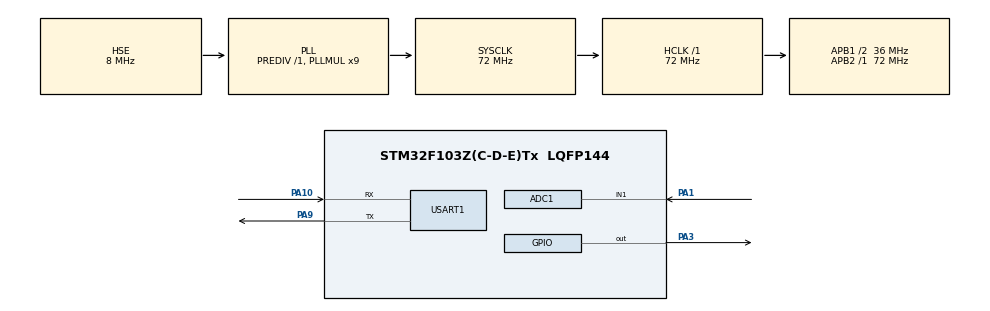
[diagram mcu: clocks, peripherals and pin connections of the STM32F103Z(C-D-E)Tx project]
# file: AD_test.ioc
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ADC1.Channel-0\#ChannelRegularConversion=ADC_CHANNEL_1
ADC1.ContinuousConvMode=DISABLE
ADC1.DataAlign=ADC_DATAALIGN_RIGHT
ADC1.DiscontinuousConvMode=DISABLE
ADC1.EnableAnalogWatchDog=false
ADC1.EnableRegularConversion=ENABLE
ADC1.ExternalTrigConv=ADC_SOFTWARE_START
ADC1.InjNumberOfConversion=0
ADC1.NbrOfConversion=1
ADC1.NbrOfConversionFlag=1
ADC1.Rank-0\#ChannelRegularConversion=1
ADC1.SamplingTime-0\#ChannelRegularConversion=ADC_SAMPLETIME_55CYCLES_5
ADC1.ScanConvMode=ADC_SCAN_DISABLE
ADC1.master=1
Mcu.Family=STM32F1
Mcu.Name=STM32F103Z(C-D-E)Tx
Mcu.Package=LQFP144
NVIC.ADC1_2_IRQn=true\:0\:0\:true\:false\:true\:true
NVIC.PriorityGroup=NVIC_PRIORITYGROUP_2
NVIC.TIM3_IRQn=true\:1\:0\:true\:false\:true\:true
OSC_IN.Mode=HSE-External-Oscillator
OSC_IN.Signal=RCC_OSC_IN
OSC_OUT.Mode=HSE-External-Oscillator
OSC_OUT.Signal=RCC_OSC_OUT
PA1.Signal=ADCx_IN1
PA10.Mode=Asynchronous
PA10.Signal=USART1_RX
PA13.Mode=Serial_Wire
PA13.Signal=SYS_JTMS-SWDIO
PA14.Mode=Serial_Wire
PA14.Signal=SYS_JTCK-SWCLK
PA3.GPIO_PuPd=GPIO_PULLDOWN
PA3.Signal=GPIO_Output
PA9.Mode=Asynchronous
PA9.Signal=USART1_TX
ProjectManager.HeapSize=0x200
ProjectManager.StackSize=0x400
ProjectManager.TargetToolchain=MDK-ARM V5
RCC.ADCPresc=RCC_ADCPCLK2_DIV6
RCC.AHBFreq_Value=72000000
RCC.APB1CLKDivider=RCC_HCLK_DIV2
RCC.APB1Freq_Value=36000000
RCC.APB1TimFreq_Value=72000000
RCC.APB2Freq_Value=72000000
RCC.APB2TimFreq_Value=72000000
RCC.HCLKFreq_Value=72000000
RCC.PLLMUL=RCC_PLL_MUL9
RCC.PLLSourceVirtual=RCC_PLLSOURCE_HSE
RCC.SYSCLKFreq_VALUE=72000000
RCC.SYSCLKSource=RCC_SYSCLKSOURCE_PLLCLK
RCC.USBFreq_Value=72000000
SH.ADCx_IN1.0=ADC1_IN1,IN1
TIM3.Period=1000
TIM3.Prescaler=72
USART1.VirtualMode=VM_ASYNC
VP_TIM3_VS_ClockSourceINT.Mode=Internal
board=custom

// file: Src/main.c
/**
  ******************************************************************************
  * @file           : main.c
  * @brief          : Main program body
  ******************************************************************************
  ** This notice applies to any and all portions of this file
  * that are not between comment pairs USER CODE BEGIN and
  * USER CODE END. Other portions of this file, whether
  * inserted by the user or by software development tools
  * are owned by their respective copyright owners.
  *
  * COPYRIGHT(c) 2018 STMicroelectronics
  *
  * Redistribution and use in source and binary forms, with or without modification,
  * are permitted provided that the following conditions are met:
  *   1. Redistributions of source code must retain the above copyright notice,
  *      this list of conditions and the following disclaimer.
  *   2. Redistributions in binary form must reproduce the above copyright notice,
  *      this list of conditions and the following disclaimer in the documentation
  *      and/or other materials provided with the distribution.
  *   3. Neither the name of STMicroelectronics nor the names of its contributors
  *      may be used to endorse or promote products derived from this software
  *      without specific prior written permission.
  *
  * THIS SOFTWARE IS PROVIDED BY THE COPYRIGHT HOLDERS AND CONTRIBUTORS "AS IS"
  * AND ANY EXPRESS OR IMPLIED WARRANTIES, INCLUDING, BUT NOT LIMITED TO, THE
  * IMPLIED WARRANTIES OF MERCHANTABILITY AND FITNESS FOR A PARTICULAR PURPOSE ARE
  * DISCLAIMED. IN NO EVENT SHALL THE COPYRIGHT HOLDER OR CONTRIBUTORS BE LIABLE
  * FOR ANY DIRECT, INDIRECT, INCIDENTAL, SPECIAL, EXEMPLARY, OR CONSEQUENTIAL
  * DAMAGES (INCLUDING, BUT NOT LIMITED TO, PROCUREMENT OF SUBSTITUTE GOODS OR
  * SERVICES; LOSS OF USE, DATA, OR PROFITS; OR BUSINESS INTERRUPTION) HOWEVER
  * CAUSED AND ON ANY THEORY OF LIABILITY, WHETHER IN CONTRACT, STRICT LIABILITY,
  * OR TORT (INCLUDING NEGLIGENCE OR OTHERWISE) ARISING IN ANY WAY OUT OF THE USE
  * OF THIS SOFTWARE, EVEN IF ADVISED OF THE POSSIBILITY OF SUCH DAMAGE.
  *
  ******************************************************************************
  */
#include "main.h"
#include "stm32f1xx_hal.h"

ADC_HandleTypeDef hadc1;

TIM_HandleTypeDef htim3;

UART_HandleTypeDef huart1;

/* USER CODE BEGIN PV */
/* Private variables ---------------------------------------------------------*/

/* USER CODE END PV */

void SystemClock_Config(void);
static void MX_GPIO_Init(void);
static void MX_ADC1_Init(void);
static void MX_USART1_UART_Init(void);
static void MX_TIM3_Init(void);

/* USER CODE BEGIN PFP */
/* Private function prototypes -----------------------------------------------*/

/* USER CODE END PFP */

/* USER CODE BEGIN 0 */
uint16_t AD_Value = 0;
float Value_1[10000]={0};
float Value_2[5000]={0};
float AD=0;
int i=-1;
float a=0; //加速度大小
//int p=0;
/* USER CODE END 0 */

int main(void)
{

  /* MCU Configuration----------------------------------------------------------*/

  /* Reset of all peripherals, Initializes the Flash interface and the Systick. */
  HAL_Init();

  /* Configure the system clock */
  SystemClock_Config();

  /* Initialize all configured peripherals */
  MX_GPIO_Init();
  MX_ADC1_Init();
  MX_USART1_UART_Init();
  MX_TIM3_Init();
  /* USER CODE BEGIN 2 */
	HAL_ADCEx_Calibration_Start(&hadc1);	//AD校准
  //HAL_Delay(3000);
	HAL_TIM_Base_Start_IT(&htim3); //启动定时器中断
	//HAL_TIM_Base_Stop_IT(&htim3);//关中断
  /* USER CODE END 2 */

  /* Infinite loop */
  while (1)
  {

  /* USER CODE BEGIN 3 */
		//HAL_ADC_Start_IT(&hadc1);
/*			HAL_ADC_Start(&hadc1);
			HAL_ADC_PollForConversion(&hadc1, 1000);	//等待转换完成，第二个参数表示超时时间，单位ms
			if(HAL_IS_BIT_SET(HAL_ADC_GetState(&hadc1), HAL_ADC_STATE_REG_EOC))
			{
				AD_Value=HAL_ADC_GetValue(&hadc1);
				AD=(float)(AD_Value*3.3/4096);
				printf("AD = %.3f \r\n",AD);
				a = (AD*1000)/(50.17*10);
				printf("%.4f \r\n",a);//HAL_Delay(1000);
			}
  htim3.Init.Prescaler = 72-1;
  htim3.Init.CounterMode = TIM_COUNTERMODE_UP;
  htim3.Init.Period = 250-1; ////计数值2000，定时2ms 1M/2ms=500次/s ， 计数值1000，定时1ms 1M/1ms=1000次/s ， 计数值500，定时500us 1M/1ms=2000次/s ，计数值250，定时250us 1M/1ms=4000次/s
		==
void HAL_TIM_PeriodElapsedCallback(TIM_HandleTypeDef *htim)
{
	HAL_ADC_Start_IT(&hadc1);
	//HAL_GPIO_TogglePin(GPIOA,GPIO_PIN_3);
}
void HAL_ADC_ConvCpltCallback(ADC_HandleTypeDef* hadc)
{
	HAL_ADC_Stop_IT(&hadc1);
	i++;
	AD_Value=HAL_ADC_GetValue(&hadc1);
	//printf("%d\r\n",i);
	if(i<10000) //0-9999
		Value_1[i]=(float)(AD_Value*3.3/4096)*1000;
	else //10000-19999
		Value_2[i-10000]=(float)(AD_Value*3.3/4096)*1000;

	if(i==14999)
	{
		HAL_TIM_Base_Stop_IT(&htim3);
		for(int j=0;j<10000;j++)
			printf("%.4f , %d\r\n",Value_1[j],j);
		for(int j=10000;j<15000;j++)
			printf("%.4f , %d\r\n",Value_2[j-10000],j-10000);
		i=-1;
		HAL_TIM_Base_Start_IT(&htim3);
	}
}
		*/
	}
  /* USER CODE END 3 */

}
void HAL_TIM_PeriodElapsedCallback(TIM_HandleTypeDef *htim)
{
	HAL_ADC_Start_IT(&hadc1);
	//HAL_GPIO_TogglePin(GPIOA,GPIO_PIN_3);
}
void HAL_ADC_ConvCpltCallback(ADC_HandleTypeDef* hadc)
{
	HAL_ADC_Stop_IT(&hadc1);	//关闭ADC
	i++;
	AD_Value=HAL_ADC_GetValue(&hadc1);
	//printf("%d\r\n",i);
	if(i<10000) //0-9999
		Value_1[i]=(float)(AD_Value*3.3/4096)*1000;
	else //10000-19999
		Value_2[i-10000]=(float)(AD_Value*3.3/4096)*1000;

	if(i==14999)
	{
		HAL_TIM_Base_Stop_IT(&htim3);
		for(int j=0;j<10000;j++)
			printf("%.4f \r\n",Value_1[j]);
		for(int j=10000;j<15000;j++)
			printf("%.4f\r\n",Value_2[j-10000]);
		i=-1;
		HAL_TIM_Base_Start_IT(&htim3);
	}
}
void SystemClock_Config(void)
{

  RCC_OscInitTypeDef RCC_OscInitStruct;
  RCC_ClkInitTypeDef RCC_ClkInitStruct;
  RCC_PeriphCLKInitTypeDef PeriphClkInit;

    /**Initializes the CPU, AHB and APB busses clocks
    */
  RCC_OscInitStruct.OscillatorType = RCC_OSCILLATORTYPE_HSE;
  RCC_OscInitStruct.HSEState = RCC_HSE_ON;
  RCC_OscInitStruct.HSEPredivValue = RCC_HSE_PREDIV_DIV1;
  RCC_OscInitStruct.HSIState = RCC_HSI_ON;
  RCC_OscInitStruct.PLL.PLLState = RCC_PLL_ON;
  RCC_OscInitStruct.PLL.PLLSource = RCC_PLLSOURCE_HSE;
  RCC_OscInitStruct.PLL.PLLMUL = RCC_PLL_MUL9;
  if (HAL_RCC_OscConfig(&RCC_OscInitStruct) != HAL_OK)
  {
    _Error_Handler(__FILE__, __LINE__);
  }

    /**Initializes the CPU, AHB and APB busses clocks
    */
  RCC_ClkInitStruct.ClockType = RCC_CLOCKTYPE_HCLK|RCC_CLOCKTYPE_SYSCLK
                              |RCC_CLOCKTYPE_PCLK1|RCC_CLOCKTYPE_PCLK2;
  RCC_ClkInitStruct.SYSCLKSource = RCC_SYSCLKSOURCE_PLLCLK;
  RCC_ClkInitStruct.AHBCLKDivider = RCC_SYSCLK_DIV1;
  RCC_ClkInitStruct.APB1CLKDivider = RCC_HCLK_DIV2;
  RCC_ClkInitStruct.APB2CLKDivider = RCC_HCLK_DIV1;

  if (HAL_RCC_ClockConfig(&RCC_ClkInitStruct, FLASH_LATENCY_2) != HAL_OK)
  {
    _Error_Handler(__FILE__, __LINE__);
  }

  PeriphClkInit.PeriphClockSelection = RCC_PERIPHCLK_ADC;
  PeriphClkInit.AdcClockSelection = RCC_ADCPCLK2_DIV6;
  if (HAL_RCCEx_PeriphCLKConfig(&PeriphClkInit) != HAL_OK)
  {
    _Error_Handler(__FILE__, __LINE__);
  }

    /**Configure the Systick interrupt time
    */
  HAL_SYSTICK_Config(HAL_RCC_GetHCLKFreq()/1000);

    /**Configure the Systick
    */
  HAL_SYSTICK_CLKSourceConfig(SYSTICK_CLKSOURCE_HCLK);

  /* SysTick_IRQn interrupt configuration */
  HAL_NVIC_SetPriority(SysTick_IRQn, 0, 0);
}

/* ADC1 init function */
static void MX_ADC1_Init(void)
{

  ADC_ChannelConfTypeDef sConfig;

    /**Common config
    */
  hadc1.Instance = ADC1;
  hadc1.Init.ScanConvMode = ADC_SCAN_DISABLE;
  hadc1.Init.ContinuousConvMode = DISABLE;
  hadc1.Init.DiscontinuousConvMode = DISABLE;
  hadc1.Init.ExternalTrigConv = ADC_SOFTWARE_START;
  hadc1.Init.DataAlign = ADC_DATAALIGN_RIGHT;
  hadc1.Init.NbrOfConversion = 1;
  if (HAL_ADC_Init(&hadc1) != HAL_OK)
  {
    _Error_Handler(__FILE__, __LINE__);
  }

    /**Configure Regular Channel
    */
  sConfig.Channel = ADC_CHANNEL_1;
  sConfig.Rank = ADC_REGULAR_RANK_1;
  sConfig.SamplingTime = ADC_SAMPLETIME_55CYCLES_5;
  if (HAL_ADC_ConfigChannel(&hadc1, &sConfig) != HAL_OK)
  {
    _Error_Handler(__FILE__, __LINE__);
  }

}

/* TIM3 init function */
static void MX_TIM3_Init(void)
{

  TIM_ClockConfigTypeDef sClockSourceConfig;
  TIM_MasterConfigTypeDef sMasterConfig;
  htim3.Instance = TIM3;
  htim3.Init.Prescaler = 72-1;
  htim3.Init.CounterMode = TIM_COUNTERMODE_UP;
  htim3.Init.Period = 2000-1;
  htim3.Init.ClockDivision = TIM_CLOCKDIVISION_DIV1;
  htim3.Init.AutoReloadPreload = TIM_AUTORELOAD_PRELOAD_DISABLE;
  if (HAL_TIM_Base_Init(&htim3) != HAL_OK)
  {
    _Error_Handler(__FILE__, __LINE__);
  }

  sClockSourceConfig.ClockSource = TIM_CLOCKSOURCE_INTERNAL;
  if (HAL_TIM_ConfigClockSource(&htim3, &sClockSourceConfig) != HAL_OK)
  {
    _Error_Handler(__FILE__, __LINE__);
  }

  sMasterConfig.MasterOutputTrigger = TIM_TRGO_RESET;
  sMasterConfig.MasterSlaveMode = TIM_MASTERSLAVEMODE_DISABLE;
  if (HAL_TIMEx_MasterConfigSynchronization(&htim3, &sMasterConfig) != HAL_OK)
  {
    _Error_Handler(__FILE__, __LINE__);
  }

}

/* USART1 init function */
static void MX_USART1_UART_Init(void)
{

  huart1.Instance = USART1;
  huart1.Init.BaudRate = 115200;
  huart1.Init.WordLength = UART_WORDLENGTH_8B;
  huart1.Init.StopBits = UART_STOPBITS_1;
  huart1.Init.Parity = UART_PARITY_NONE;
  huart1.Init.Mode = UART_MODE_TX_RX;
  huart1.Init.HwFlowCtl = UART_HWCONTROL_NONE;
  huart1.Init.OverSampling = UART_OVERSAMPLING_16;
  if (HAL_UART_Init(&huart1) != HAL_OK)
  {
    _Error_Handler(__FILE__, __LINE__);
  }

}

/** Configure pins as
        * Analog
        * Input
        * Output
        * EVENT_OUT
        * EXTI
*/
static void MX_GPIO_Init(void)
{

  GPIO_InitTypeDef GPIO_InitStruct;

  /* GPIO Ports Clock Enable */
  __HAL_RCC_GPIOA_CLK_ENABLE();

  /*Configure GPIO pin Output Level */
  HAL_GPIO_WritePin(GPIOA, GPIO_PIN_3, GPIO_PIN_RESET);

  /*Configure GPIO pin : PA3 */
  GPIO_InitStruct.Pin = GPIO_PIN_3;
  GPIO_InitStruct.Mode = GPIO_MODE_OUTPUT_PP;
  GPIO_InitStruct.Pull = GPIO_PULLDOWN;
  GPIO_InitStruct.Speed = GPIO_SPEED_FREQ_LOW;
  HAL_GPIO_Init(GPIOA, &GPIO_InitStruct);

}

void _Error_Handler(char *file, int line)
{
  while(1)
  {
  }
}

/************************ (C) COPYRIGHT STMicroelectronics *****END OF FILE****/
